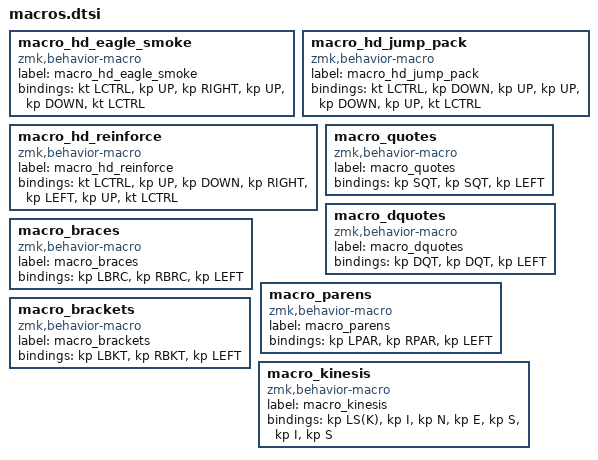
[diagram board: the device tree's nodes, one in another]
macro_hd_eagle_smoke: macro_hd_eagle_smoke{
compatible = "zmk,behavior-macro";
label = "macro_hd_eagle_smoke";
#binding-cells = <0>;
bindings = <&kt LCTRL>, <&kp UP>, <&kp RIGHT>, <&kp UP>, <&kp DOWN>, <&kt LCTRL>;
};
macro_hd_jump_pack: macro_hd_jump_pack{
compatible = "zmk,behavior-macro";
label = "macro_hd_jump_pack";
#binding-cells = <0>;
bindings = <&kt LCTRL>, <&kp DOWN>, <&kp UP>, <&kp UP>, <&kp DOWN>, <&kp UP>, <&kt LCTRL>;
};
macro_hd_reinforce: macro_hd_reinforce{
compatible = "zmk,behavior-macro";
label = "macro_hd_reinforce";
#binding-cells = <0>;
bindings = <&kt LCTRL>, <&kp UP>, <&kp DOWN>, <&kp RIGHT>, <&kp LEFT>, <&kp UP>, <&kt LCTRL>;
};
macro_quotes: macro_quotes{
compatible = "zmk,behavior-macro";
label = "macro_quotes";
#binding-cells = <0>;
bindings = <&kp SQT>, <&kp SQT>, <&kp LEFT>;
};
macro_dquotes: macro_dquotes{
compatible = "zmk,behavior-macro";
label = "macro_dquotes";
#binding-cells = <0>;
bindings = <&kp DQT>, <&kp DQT>, <&kp LEFT>;
};
macro_braces: macro_braces{
compatible = "zmk,behavior-macro";
label = "macro_braces";
#binding-cells = <0>;
bindings = <&kp LBRC>, <&kp RBRC>, <&kp LEFT>;
};
macro_parens: macro_parens{
compatible = "zmk,behavior-macro";
label = "macro_parens";
#binding-cells = <0>;
bindings = <&kp LPAR>, <&kp RPAR>, <&kp LEFT>;
};
macro_brackets: macro_brackets{
compatible = "zmk,behavior-macro";
label = "macro_brackets";
#binding-cells = <0>;
bindings = <&kp LBKT>, <&kp RBKT>, <&kp LEFT>;
};
macro_kinesis: macro_kinesis{
compatible = "zmk,behavior-macro";
label = "macro_kinesis";
#binding-cells = <0>;
bindings = <&kp LS(K)>, <&kp I>, <&kp N>, <&kp E>, <&kp S>, <&kp I>, <&kp S>;
};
